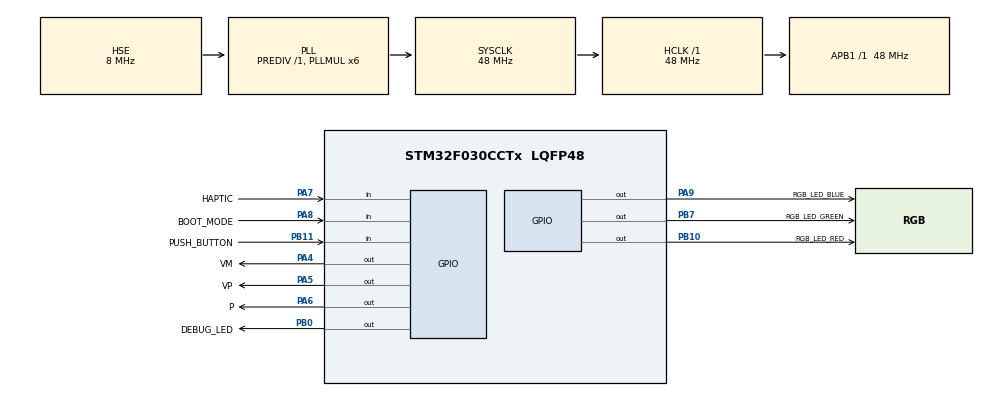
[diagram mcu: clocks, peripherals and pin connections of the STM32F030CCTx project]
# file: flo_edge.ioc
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Mcu.Family=STM32F0
Mcu.Name=STM32F030CCTx
Mcu.Package=LQFP48
PA4.GPIO_Label=VM
PA4.Signal=GPIO_Output
PA5.GPIO_Label=VP
PA5.Signal=GPIO_Output
PA6.GPIO_Label=P
PA6.Signal=GPIO_Output
PA7.GPIO_Label=HAPTIC
PA7.GPIO_PuPd=GPIO_PULLDOWN
PA7.Signal=GPIO_Input
PA8.GPIO_Label=BOOT_MODE
PA8.GPIO_PuPd=GPIO_PULLUP
PA8.Signal=GPIO_Input
PA9.GPIO_Label=RGB_LED_BLUE
PA9.Signal=GPIO_Output
PB0.GPIO_Label=DEBUG_LED
PB0.Signal=GPIO_Output
PB10.GPIO_Label=RGB_LED_RED
PB10.Signal=GPIO_Output
PB11.GPIO_Label=PUSH_BUTTON
PB11.GPIO_PuPd=GPIO_PULLUP
PB11.Signal=GPIO_Input
PB7.GPIO_Label=RGB_LED_GREEN
PB7.Signal=GPIO_Output
PF0-OSC_IN.Mode=HSE-External-Oscillator
PF0-OSC_IN.Signal=RCC_OSC_IN
PF1-OSC_OUT.Mode=HSE-External-Oscillator
PF1-OSC_OUT.Signal=RCC_OSC_OUT
ProjectManager.HeapSize=0x200
ProjectManager.StackSize=0x400
ProjectManager.TargetToolchain=STM32CubeIDE
RCC.AHBFreq_Value=48000000
RCC.APB1Freq_Value=48000000
RCC.APB1TimFreq_Value=48000000
RCC.HCLKFreq_Value=48000000
RCC.PLLMUL=RCC_PLL_MUL6
RCC.PLLSourceVirtual=RCC_PLLSOURCE_HSE
RCC.SYSCLKFreq_VALUE=48000000
RCC.SYSCLKSource=RCC_SYSCLKSOURCE_PLLCLK
board=custom

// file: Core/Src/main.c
/* USER CODE BEGIN Header */
/**
  ******************************************************************************
  * @file           : main.c
  * @brief          : Main program body
  ******************************************************************************
  * @attention
  *
  * Copyright (c) 2023 STMicroelectronics.
  * All rights reserved.
  *
  * This software is licensed under terms that can be found in the LICENSE file
  * in the root directory of this software component.
  * If no LICENSE file comes with this software, it is provided AS-IS.
  *
  ******************************************************************************
  */
/* USER CODE END Header */
#include "main.h"

/* USER CODE BEGIN Includes */
#include "flo_edge.h"
/* USER CODE END Includes */

void SystemClock_Config(void);
static void MX_GPIO_Init(void);

int main(void)
{

  /* MCU Configuration--------------------------------------------------------*/

  /* Reset of all peripherals, Initializes the Flash interface and the Systick. */
  HAL_Init();

  /* Configure the system clock */
  SystemClock_Config();

  /* Initialize all configured peripherals */
  MX_GPIO_Init();
  /* USER CODE BEGIN 2 */

  flo_edge_init();
  while(1){
	  flo_edge_main();
  }
}

void SystemClock_Config(void)
{
  RCC_OscInitTypeDef RCC_OscInitStruct = {0};
  RCC_ClkInitTypeDef RCC_ClkInitStruct = {0};

  /** Initializes the RCC Oscillators according to the specified parameters
  * in the RCC_OscInitTypeDef structure.
  */
  RCC_OscInitStruct.OscillatorType = RCC_OSCILLATORTYPE_HSE;
  RCC_OscInitStruct.HSEState = RCC_HSE_ON;
  RCC_OscInitStruct.PLL.PLLState = RCC_PLL_ON;
  RCC_OscInitStruct.PLL.PLLSource = RCC_PLLSOURCE_HSE;
  RCC_OscInitStruct.PLL.PLLMUL = RCC_PLL_MUL6;
  RCC_OscInitStruct.PLL.PREDIV = RCC_PREDIV_DIV1;
  if (HAL_RCC_OscConfig(&RCC_OscInitStruct) != HAL_OK)
  {
    Error_Handler();
  }

  /** Initializes the CPU, AHB and APB buses clocks
  */
  RCC_ClkInitStruct.ClockType = RCC_CLOCKTYPE_HCLK|RCC_CLOCKTYPE_SYSCLK
                              |RCC_CLOCKTYPE_PCLK1;
  RCC_ClkInitStruct.SYSCLKSource = RCC_SYSCLKSOURCE_PLLCLK;
  RCC_ClkInitStruct.AHBCLKDivider = RCC_SYSCLK_DIV1;
  RCC_ClkInitStruct.APB1CLKDivider = RCC_HCLK_DIV1;

  if (HAL_RCC_ClockConfig(&RCC_ClkInitStruct, FLASH_LATENCY_1) != HAL_OK)
  {
    Error_Handler();
  }
}

static void MX_GPIO_Init(void)
{
  GPIO_InitTypeDef GPIO_InitStruct = {0};

  /* GPIO Ports Clock Enable */
  __HAL_RCC_GPIOF_CLK_ENABLE();
  __HAL_RCC_GPIOA_CLK_ENABLE();
  __HAL_RCC_GPIOB_CLK_ENABLE();

  /*Configure GPIO pin Output Level */
  HAL_GPIO_WritePin(GPIOA, VM_Pin|VP_Pin|P_Pin|RGB_LED_BLUE_Pin, GPIO_PIN_RESET);

  /*Configure GPIO pin Output Level */
  HAL_GPIO_WritePin(GPIOB, DEBUG_LED_Pin|RGB_LED_RED_Pin|RGB_LED_GREEN_Pin, GPIO_PIN_RESET);

  /*Configure GPIO pins : VM_Pin VP_Pin P_Pin RGB_LED_BLUE_Pin */
  GPIO_InitStruct.Pin = VM_Pin|VP_Pin|P_Pin|RGB_LED_BLUE_Pin;
  GPIO_InitStruct.Mode = GPIO_MODE_OUTPUT_PP;
  GPIO_InitStruct.Pull = GPIO_NOPULL;
  GPIO_InitStruct.Speed = GPIO_SPEED_FREQ_LOW;
  HAL_GPIO_Init(GPIOA, &GPIO_InitStruct);

  /*Configure GPIO pin : HAPTIC_Pin */
  GPIO_InitStruct.Pin = HAPTIC_Pin;
  GPIO_InitStruct.Mode = GPIO_MODE_INPUT;
  GPIO_InitStruct.Pull = GPIO_PULLDOWN;
  HAL_GPIO_Init(HAPTIC_GPIO_Port, &GPIO_InitStruct);

  /*Configure GPIO pins : DEBUG_LED_Pin RGB_LED_RED_Pin RGB_LED_GREEN_Pin */
  GPIO_InitStruct.Pin = DEBUG_LED_Pin|RGB_LED_RED_Pin|RGB_LED_GREEN_Pin;
  GPIO_InitStruct.Mode = GPIO_MODE_OUTPUT_PP;
  GPIO_InitStruct.Pull = GPIO_NOPULL;
  GPIO_InitStruct.Speed = GPIO_SPEED_FREQ_LOW;
  HAL_GPIO_Init(GPIOB, &GPIO_InitStruct);

  /*Configure GPIO pin : PUSH_BUTTON_Pin */
  GPIO_InitStruct.Pin = PUSH_BUTTON_Pin;
  GPIO_InitStruct.Mode = GPIO_MODE_INPUT;
  GPIO_InitStruct.Pull = GPIO_PULLUP;
  HAL_GPIO_Init(PUSH_BUTTON_GPIO_Port, &GPIO_InitStruct);

  /*Configure GPIO pin : BOOT_MODE_Pin */
  GPIO_InitStruct.Pin = BOOT_MODE_Pin;
  GPIO_InitStruct.Mode = GPIO_MODE_INPUT;
  GPIO_InitStruct.Pull = GPIO_PULLUP;
  HAL_GPIO_Init(BOOT_MODE_GPIO_Port, &GPIO_InitStruct);

}

void Error_Handler(void)
{
  __disable_irq();
  while (1)
  {
  }
}
